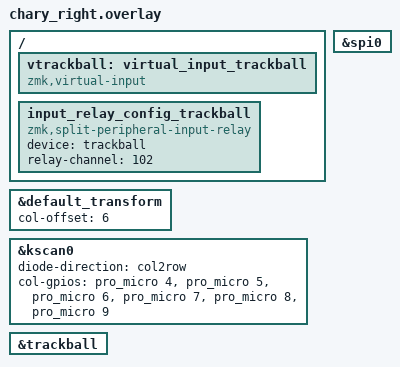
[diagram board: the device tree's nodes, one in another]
/*
 * Copyright (c) 2022 Duccio Breschi
 *
 * SPDX-License-Identifier: MIT
 */

#include "chary.dtsi"
#include "charybdis_3610.dtsi"

&default_transform {
    col-offset = <6>;
};

&kscan0 {
    diode-direction = "col2row";
    col-gpios
        = <&pro_micro 4 (GPIO_ACTIVE_HIGH)> // COL0
        , <&pro_micro 5 (GPIO_ACTIVE_HIGH)> // COL1
        , <&pro_micro 6 (GPIO_ACTIVE_HIGH)> // COL2
        , <&pro_micro 7 (GPIO_ACTIVE_HIGH)> // COL3
	    , <&pro_micro 8 (GPIO_ACTIVE_HIGH)> // COL4
        , <&pro_micro 9 (GPIO_ACTIVE_HIGH)> // COL5
    ;
};

&spi0 {
    status = "okay";
};

&trackball {
    status = "okay";
};

/ {
	vtrackball: virtual_input_trackball {
		compatible = "zmk,virtual-input";
	};

	input_relay_config_trackball {
		compatible = "zmk,split-peripheral-input-relay";
		device = <&trackball>;
		relay-channel = <102>;
	};
};
